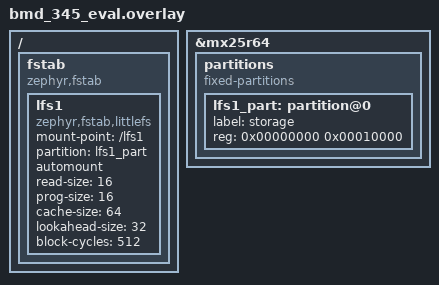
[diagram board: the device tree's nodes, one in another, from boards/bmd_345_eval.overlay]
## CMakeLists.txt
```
#
# Copyright (c) 2019 Peter Bigot Consulting, LLC
#
# SPDX-License-Identifier: Apache-2.0
#

cmake_minimum_required(VERSION 3.13.1)
find_package(Zephyr REQUIRED HINTS $ENV{ZEPHYR_BASE})
project(littlefs)

FILE(GLOB app_sources src/*.c)
target_sources(app PRIVATE ${app_sources})
```

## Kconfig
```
# Copyright (c) 2019 Peter Bigot Consulting, LLC
# SPDX-License-Identifier: Apache-2.0

mainmenu "littlefs sample"

config APP_WIPE_STORAGE
	bool "Option to clear the flash area before mounting"
	help
	  Use this to force an existing file system to be created.

source "Kconfig.zephyr"
```

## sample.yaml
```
sample:
  name: littlefs filesystem sample
tests:
  sample.filesystem.littlefs:
    build_only: true
    platform_allow: nrf52840dk_nrf52840 particle_xenon disco_l475_iot1
      mimxrt685_evk_cm33 mimxrt1060_evk mimxrt1064_evk qemu_x86 native_posix
    tags: filesystem
```

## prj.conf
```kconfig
#
# Copyright (c) 2019 Peter Bigot Consulting, LLC
#
# SPDX-License-Identifier: Apache-2.0
#

# Optionally force the file system to be recreated
#CONFIG_APP_WIPE_STORAGE=y

# fs_dirent structures are big.
CONFIG_MAIN_STACK_SIZE=2048

# Let __ASSERT do its job
CONFIG_DEBUG=y

CONFIG_LOG=y

CONFIG_FLASH=y
CONFIG_FLASH_MAP=y
CONFIG_FLASH_PAGE_LAYOUT=y

CONFIG_FILE_SYSTEM=y
CONFIG_FILE_SYSTEM_LITTLEFS=y
```

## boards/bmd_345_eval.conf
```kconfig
#
# Copyright (c) 2021 Linumiz
#
# SPDX-License-Identifier: Apache-2.0

# Need this when storage is on flash
CONFIG_MPU_ALLOW_FLASH_WRITE=y

# Need this when storage is on MX25R64
CONFIG_NORDIC_QSPI_NOR=y
CONFIG_NORDIC_QSPI_NOR_FLASH_LAYOUT_PAGE_SIZE=4096
```

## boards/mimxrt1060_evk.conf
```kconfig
#
# Copyright (c) 2021 NXP.
# SPDX-License-Identifier: Apache-2.0
#

# Need this when storage is on flash
CONFIG_MPU_ALLOW_FLASH_WRITE=y
```

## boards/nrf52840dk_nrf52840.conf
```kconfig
#
# Copyright (c) 2019 Peter Bigot Consulting, LLC
# Copyright (c) 2019 Nordic Semiconductor ASA
#
# SPDX-License-Identifier: Apache-2.0
#

# Need this when storage is on flash
CONFIG_MPU_ALLOW_FLASH_WRITE=y

# Need this when storage is on MX25R64
CONFIG_NORDIC_QSPI_NOR=y
CONFIG_NORDIC_QSPI_NOR_FLASH_LAYOUT_PAGE_SIZE=4096
```

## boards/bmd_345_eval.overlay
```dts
/*
 * Copyright (c) 2021 Linumiz
 *
 * SPDX-License-Identifier: Apache-2.0
 */

/delete-node/ &storage_partition;

/ {
	fstab {
		compatible = "zephyr,fstab";
		lfs1: lfs1 {
			compatible = "zephyr,fstab,littlefs";
			mount-point = "/lfs1";
			partition = <&lfs1_part>;
			automount;
			read-size = <16>;
			prog-size = <16>;
			cache-size = <64>;
			lookahead-size = <32>;
			block-cycles = <512>;
		};
	};
};

&mx25r64 {
	partitions {
		compatible = "fixed-partitions";
		#address-cells = <1>;
		#size-cells = <1>;

		lfs1_part: partition@0 {
			label = "storage";
			reg = <0x00000000 0x00010000>;
		};
	};
};
```

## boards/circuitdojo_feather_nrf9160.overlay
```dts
/*
 * Copyright (c) 2020 Circuit Dojo LLC
 *
 * SPDX-License-Identifier: Apache-2.0
 */

/delete-node/ &storage_partition;

&w25q16jv {
	partitions {
		compatible = "fixed-partitions";
		#address-cells = <1>;
		#size-cells = <1>;

		partition@0 {
			label = "storage";
			reg = <0x00000000 0x00010000>;
		};
	};
};
```

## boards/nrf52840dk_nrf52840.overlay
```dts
/*
 * Copyright (c) 2019 Peter Bigot Consulting, LLC
 *
 * SPDX-License-Identifier: Apache-2.0
 */

/delete-node/ &storage_partition;

/ {
	fstab {
		compatible = "zephyr,fstab";
		lfs1: lfs1 {
			compatible = "zephyr,fstab,littlefs";
			mount-point = "/lfs1";
			partition = <&lfs1_part>;
			automount;
			read-size = <16>;
			prog-size = <16>;
			cache-size = <64>;
			lookahead-size = <32>;
			block-cycles = <512>;
		};
	};
};

&mx25r64 {
	partitions {
		compatible = "fixed-partitions";
		#address-cells = <1>;
		#size-cells = <1>;

		lfs1_part: partition@0 {
			label = "storage";
			reg = <0x00000000 0x00010000>;
		};
	};
};
```

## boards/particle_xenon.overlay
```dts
/*
 * Copyright (c) 2019 Peter Bigot Consulting, LLC
 *
 * SPDX-License-Identifier: Apache-2.0
 */

/delete-node/ &storage_partition;

&mx25l32 {
	partitions {
		compatible = "fixed-partitions";
		#address-cells = <1>;
		#size-cells = <1>;

		/* This is the littlefs v1 file system pre-installed
		 * by Particle.
		 */
		littlefs_partition: partition@0 {
			label = "littlefs";
			reg = <0x00000000 0x00200000>;
		};
		/* A 16 KiBy partition to use for the test. */
		storage_partition: partition@200000 {
			label = "storage";
			reg = <0x00200000 0x00004000>;
		};
		/* A bigger partition for something else. */
		partition@204000 {
			label = "scratch";
			reg = <0x00204000 0x001fc000>;
		};
	};
};
```

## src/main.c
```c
/*
 * Copyright (c) 2019 Peter Bigot Consulting, LLC
 *
 * SPDX-License-Identifier: Apache-2.0
 */

/* Sample which uses the filesystem API with littlefs */

#include <stdio.h>

#include <zephyr.h>
#include <device.h>
#include <fs/fs.h>
#include <fs/littlefs.h>
#include <storage/flash_map.h>

/* Matches LFS_NAME_MAX */
#define MAX_PATH_LEN 255

#define PARTITION_NODE DT_NODELABEL(lfs1)

#if DT_NODE_EXISTS(PARTITION_NODE)
FS_FSTAB_DECLARE_ENTRY(PARTITION_NODE);
#else /* PARTITION_NODE */
FS_LITTLEFS_DECLARE_DEFAULT_CONFIG(storage);
static struct fs_mount_t lfs_storage_mnt = {
	.type = FS_LITTLEFS,
	.fs_data = &storage,
	.storage_dev = (void *)FLASH_AREA_ID(storage),
	.mnt_point = "/lfs",
};
#endif /* PARTITION_NODE */

void main(void)
{
	struct fs_mount_t *mp =
#if DT_NODE_EXISTS(PARTITION_NODE)
		&FS_FSTAB_ENTRY(PARTITION_NODE)
#else
		&lfs_storage_mnt
#endif
		;
	unsigned int id = (uintptr_t)mp->storage_dev;
	char fname[MAX_PATH_LEN];
	struct fs_statvfs sbuf;
	const struct flash_area *pfa;
	int rc;

	snprintf(fname, sizeof(fname), "%s/boot_count", mp->mnt_point);

	rc = flash_area_open(id, &pfa);
	if (rc < 0) {
		printk("FAIL: unable to find flash area %u: %d\n",
		       id, rc);
		return;
	}

	printk("Area %u at 0x%x on %s for %u bytes\n",
	       id, (unsigned int)pfa->fa_off, pfa->fa_dev_name,
	       (unsigned int)pfa->fa_size);

	/* Optional wipe flash contents */
	if (IS_ENABLED(CONFIG_APP_WIPE_STORAGE)) {
		printk("Erasing flash area ... ");
		rc = flash_area_erase(pfa, 0, pfa->fa_size);
		printk("%d\n", rc);
	}

	flash_area_close(pfa);

	/* Do not mount if auto-mount has been enabled */
#if !DT_NODE_EXISTS(PARTITION_NODE) ||						\
	!(FSTAB_ENTRY_DT_MOUNT_FLAGS(PARTITION_NODE) & FS_MOUNT_FLAG_AUTOMOUNT)
	rc = fs_mount(mp);
	if (rc < 0) {
		printk("FAIL: mount id %u at %s: %d\n",
		       (unsigned int)mp->storage_dev, mp->mnt_point,
		       rc);
		return;
	}
	printk("%s mount: %d\n", mp->mnt_point, rc);
#else
	printk("%s automounted\n", mp->mnt_point);
#endif

	rc = fs_statvfs(mp->mnt_point, &sbuf);
	if (rc < 0) {
		printk("FAIL: statvfs: %d\n", rc);
		goto out;
	}

	printk("%s: bsize = %lu ; frsize = %lu ;"
	       " blocks = %lu ; bfree = %lu\n",
	       mp->mnt_point,
	       sbuf.f_bsize, sbuf.f_frsize,
	       sbuf.f_blocks, sbuf.f_bfree);

	struct fs_dirent dirent;

	rc = fs_stat(fname, &dirent);
	printk("%s stat: %d\n", fname, rc);
	if (rc >= 0) {
		printk("\tfn '%s' siz %u\n", dirent.name, dirent.size);
	}

	struct fs_file_t file;

	fs_file_t_init(&file);

	rc = fs_open(&file, fname, FS_O_CREATE | FS_O_RDWR);
	if (rc < 0) {
		printk("FAIL: open %s: %d\n", fname, rc);
		goto out;
	}

	uint32_t boot_count = 0;

	if (rc >= 0) {
		rc = fs_read(&file, &boot_count, sizeof(boot_count));
		printk("%s read count %u: %d\n", fname, boot_count, rc);
		rc = fs_seek(&file, 0, FS_SEEK_SET);
		printk("%s seek start: %d\n", fname, rc);

	}

	boot_count += 1;
	rc = fs_write(&file, &boot_count, sizeof(boot_count));
	printk("%s write new boot count %u: %d\n", fname,
	       boot_count, rc);

	rc = fs_close(&file);
	printk("%s close: %d\n", fname, rc);

	struct fs_dir_t dir;

	fs_dir_t_init(&dir);

	rc = fs_opendir(&dir, mp->mnt_point);
	printk("%s opendir: %d\n", mp->mnt_point, rc);

	while (rc >= 0) {
		struct fs_dirent ent = { 0 };

		rc = fs_readdir(&dir, &ent);
		if (rc < 0) {
			break;
		}
		if (ent.name[0] == 0) {
			printk("End of files\n");
			break;
		}
		printk("  %c %u %s\n",
		       (ent.type == FS_DIR_ENTRY_FILE) ? 'F' : 'D',
		       ent.size,
		       ent.name);
	}

	(void)fs_closedir(&dir);

out:
	rc = fs_unmount(mp);
	printk("%s unmount: %d\n", mp->mnt_point, rc);
}
```
